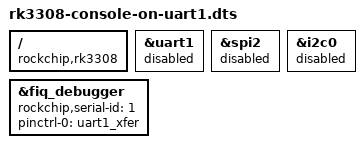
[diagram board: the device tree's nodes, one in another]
/dts-v1/;
/plugin/;

/ {
	compatible = "rockchip,rk3308";

	fragment@0 {
		target = <&uart1>;
		__overlay__ {
			status = "disabled";
		};
	};

	fragment@1 {
		target = <&spi2>;
		__overlay__ {
			status = "disabled";
		};
	};

	fragment@2 {
		target = <&i2c0>;
		__overlay__ {
			status = "disabled";
		};
	};

	fragment@3 {
		target = <&fiq_debugger>;
		__overlay__ {
			status = "okay";
			rockchip,serial-id = <1>;
			pinctrl-names = "default";
			pinctrl-0 = <&uart1_xfer>;
		};
	};
};
